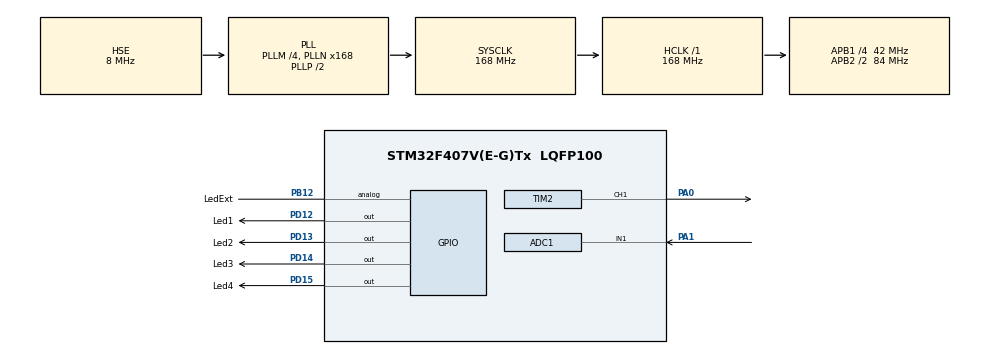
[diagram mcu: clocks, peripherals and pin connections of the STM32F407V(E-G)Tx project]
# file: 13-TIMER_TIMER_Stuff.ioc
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ADC1.Channel-3\#ChannelRegularConversion=ADC_CHANNEL_1
ADC1.ContinuousConvMode=DISABLE
ADC1.EOCSelection=ADC_EOC_SINGLE_CONV
ADC1.ExternalTrigConv=ADC_EXTERNALTRIGCONV_T3_TRGO
ADC1.NbrOfConversion=1
ADC1.NbrOfConversionFlag=1
ADC1.Rank-3\#ChannelRegularConversion=1
ADC1.Resolution=ADC_RESOLUTION_12B
ADC1.SamplingTime-3\#ChannelRegularConversion=ADC_SAMPLETIME_28CYCLES
ADC1.ScanConvMode=DISABLE
ADC1.master=1
Mcu.Family=STM32F4
Mcu.Name=STM32F407V(E-G)Tx
Mcu.Package=LQFP100
NVIC.ADC_IRQn=true\:0\:0\:false\:false\:true\:true\:true
NVIC.PriorityGroup=NVIC_PRIORITYGROUP_4
PA0-WKUP.Signal=S_TIM2_CH1_ETR
PA1.Signal=ADCx_IN1
PB12.GPIO_Label=LedExt
PB12.Signal=GPIO_Analog
PD12.GPIO_Label=Led1
PD12.Signal=GPIO_Output
PD13.GPIO_Label=Led2
PD13.Signal=GPIO_Output
PD14.GPIO_Label=Led3
PD14.Signal=GPIO_Output
PD15.GPIO_Label=Led4
PD15.Signal=GPIO_Output
PH0-OSC_IN.Mode=HSE-External-Oscillator
PH0-OSC_IN.Signal=RCC_OSC_IN
PH1-OSC_OUT.Mode=HSE-External-Oscillator
PH1-OSC_OUT.Signal=RCC_OSC_OUT
ProjectManager.HeapSize=0x200
ProjectManager.StackSize=0x400
ProjectManager.TargetToolchain=MDK-ARM V5.27
RCC.48MHZClocksFreq_Value=84000000
RCC.AHBFreq_Value=168000000
RCC.APB1CLKDivider=RCC_HCLK_DIV4
RCC.APB1Freq_Value=42000000
RCC.APB1TimFreq_Value=84000000
RCC.APB2CLKDivider=RCC_HCLK_DIV2
RCC.APB2Freq_Value=84000000
RCC.APB2TimFreq_Value=168000000
RCC.CortexFreq_Value=168000000
RCC.HCLKFreq_Value=168000000
RCC.HSE_VALUE=8000000
RCC.HSI_VALUE=16000000
RCC.LSE_VALUE=32768
RCC.PLLM=4
RCC.PLLN=168
RCC.PLLSourceVirtual=RCC_PLLSOURCE_HSE
RCC.SYSCLKFreq_VALUE=168000000
RCC.SYSCLKSource=RCC_SYSCLKSOURCE_PLLCLK
RCC.VCOOutputFreq_Value=336000000
SH.ADCx_IN1.0=ADC1_IN1,IN1
SH.S_TIM2_CH1_ETR.0=TIM2_CH1,PWM Generation1 CH1
TIM2.AutoReloadPreload=TIM_AUTORELOAD_PRELOAD_ENABLE
TIM2.Channel-PWM\ Generation1\ CH1=TIM_CHANNEL_1
TIM2.Period=65535
TIM3.AutoReloadPreload=TIM_AUTORELOAD_PRELOAD_ENABLE
TIM3.Period=8400
TIM3.Prescaler=1000
TIM3.TIM_MasterOutputTrigger=TIM_TRGO_UPDATE
VP_TIM2_VS_ClockSourceINT.Mode=Internal
VP_TIM3_VS_ClockSourceINT.Mode=Internal
board=custom

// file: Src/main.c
/* USER CODE BEGIN Header */
/**
  ******************************************************************************
  * @file           : main.c
  * @brief          : Main program body
  ******************************************************************************
  * @attention
  *
  * <h2><center>&copy; Copyright (c) 2020 STMicroelectronics.
  * All rights reserved.</center></h2>
  *
  * This software component is licensed by ST under BSD 3-Clause license,
  * the "License"; You may not use this file except in compliance with the
  * License. You may obtain a copy of the License at:
  *                        opensource.org/licenses/BSD-3-Clause
  *
  ******************************************************************************
  */
/* USER CODE END Header */

#include "main.h"

ADC_HandleTypeDef hadc1;

TIM_HandleTypeDef htim2;
TIM_HandleTypeDef htim3;

void SystemClock_Config(void);
static void MX_GPIO_Init(void);
static void MX_TIM2_Init(void);
static void MX_TIM3_Init(void);
static void MX_ADC1_Init(void);

/* USER CODE BEGIN 0 */
int32_t CH1_DC = 0;
uint16_t load;
uint16_t adcval;
/* USER CODE END 0 */

int main(void)
{

  /* MCU Configuration--------------------------------------------------------*/

  /* Reset of all peripherals, Initializes the Flash interface and the Systick. */
  HAL_Init();

  /* Configure the system clock */
  SystemClock_Config();

  /* Initialize all configured peripherals */
  MX_GPIO_Init();
  MX_TIM2_Init();
  MX_TIM3_Init();
  MX_ADC1_Init();
  /* USER CODE BEGIN 2 */

	HAL_ADC_Start_IT(&hadc1);
	HAL_TIM_Base_Start(&htim3);

	HAL_TIM_PWM_Start(&htim2, TIM_CHANNEL_1);

	//CH1_DC = 65534;
  /* USER CODE END 2 */

  /* Infinite loop */
  while (1)
  {

    /* USER CODE BEGIN 3 */

//		while(CH1_DC < 65535)
//    	{
//    	    TIM2->CCR1 = CH1_DC; // = CH1_DC
//    	    CH1_DC+=50;				 // += 70;
//    	    HAL_Delay(1);
//    	}
//    	while(CH1_DC > 0)
//    	{
//    	    TIM2->CCR1 = CH1_DC; //TIM2->CCR1 = CH1_DC;
//    	    CH1_DC-=50;
//    	    HAL_Delay(1);
//    	}
//			HAL_Delay(500);

	//		TIM2->CCR1 = adcval*16;
  }
  /* USER CODE END 3 */
}

void SystemClock_Config(void)
{
  RCC_OscInitTypeDef RCC_OscInitStruct = {0};
  RCC_ClkInitTypeDef RCC_ClkInitStruct = {0};

  /** Configure the main internal regulator output voltage
  */
  __HAL_RCC_PWR_CLK_ENABLE();
  __HAL_PWR_VOLTAGESCALING_CONFIG(PWR_REGULATOR_VOLTAGE_SCALE1);
  /** Initializes the CPU, AHB and APB busses clocks
  */
  RCC_OscInitStruct.OscillatorType = RCC_OSCILLATORTYPE_HSE;
  RCC_OscInitStruct.HSEState = RCC_HSE_ON;
  RCC_OscInitStruct.PLL.PLLState = RCC_PLL_ON;
  RCC_OscInitStruct.PLL.PLLSource = RCC_PLLSOURCE_HSE;
  RCC_OscInitStruct.PLL.PLLM = 4;
  RCC_OscInitStruct.PLL.PLLN = 168;
  RCC_OscInitStruct.PLL.PLLP = RCC_PLLP_DIV2;
  RCC_OscInitStruct.PLL.PLLQ = 4;
  if (HAL_RCC_OscConfig(&RCC_OscInitStruct) != HAL_OK)
  {
    Error_Handler();
  }
  /** Initializes the CPU, AHB and APB busses clocks
  */
  RCC_ClkInitStruct.ClockType = RCC_CLOCKTYPE_HCLK|RCC_CLOCKTYPE_SYSCLK
                              |RCC_CLOCKTYPE_PCLK1|RCC_CLOCKTYPE_PCLK2;
  RCC_ClkInitStruct.SYSCLKSource = RCC_SYSCLKSOURCE_PLLCLK;
  RCC_ClkInitStruct.AHBCLKDivider = RCC_SYSCLK_DIV1;
  RCC_ClkInitStruct.APB1CLKDivider = RCC_HCLK_DIV4;
  RCC_ClkInitStruct.APB2CLKDivider = RCC_HCLK_DIV2;

  if (HAL_RCC_ClockConfig(&RCC_ClkInitStruct, FLASH_LATENCY_5) != HAL_OK)
  {
    Error_Handler();
  }
}

static void MX_ADC1_Init(void)
{

  ADC_ChannelConfTypeDef sConfig = {0};

  /** Configure the global features of the ADC (Clock, Resolution, Data Alignment and number of conversion)
  */
  hadc1.Instance = ADC1;
  hadc1.Init.ClockPrescaler = ADC_CLOCK_SYNC_PCLK_DIV4;
  hadc1.Init.Resolution = ADC_RESOLUTION_12B;
  hadc1.Init.ScanConvMode = DISABLE;
  hadc1.Init.ContinuousConvMode = DISABLE;
  hadc1.Init.DiscontinuousConvMode = DISABLE;
  hadc1.Init.ExternalTrigConvEdge = ADC_EXTERNALTRIGCONVEDGE_RISING;
  hadc1.Init.ExternalTrigConv = ADC_EXTERNALTRIGCONV_T3_TRGO;
  hadc1.Init.DataAlign = ADC_DATAALIGN_RIGHT;
  hadc1.Init.NbrOfConversion = 1;
  hadc1.Init.DMAContinuousRequests = DISABLE;
  hadc1.Init.EOCSelection = ADC_EOC_SINGLE_CONV;
  if (HAL_ADC_Init(&hadc1) != HAL_OK)
  {
    Error_Handler();
  }
  /** Configure for the selected ADC regular channel its corresponding rank in the sequencer and its sample time.
  */
  sConfig.Channel = ADC_CHANNEL_1;
  sConfig.Rank = 1;
  sConfig.SamplingTime = ADC_SAMPLETIME_28CYCLES;
  if (HAL_ADC_ConfigChannel(&hadc1, &sConfig) != HAL_OK)
  {
    Error_Handler();
  }

}

static void MX_TIM2_Init(void)
{

  TIM_ClockConfigTypeDef sClockSourceConfig = {0};
  TIM_MasterConfigTypeDef sMasterConfig = {0};
  TIM_OC_InitTypeDef sConfigOC = {0};

  htim2.Instance = TIM2;
  htim2.Init.Prescaler = 0;
  htim2.Init.CounterMode = TIM_COUNTERMODE_UP;
  htim2.Init.Period = 65535;
  htim2.Init.ClockDivision = TIM_CLOCKDIVISION_DIV1;
  htim2.Init.AutoReloadPreload = TIM_AUTORELOAD_PRELOAD_ENABLE;
  if (HAL_TIM_Base_Init(&htim2) != HAL_OK)
  {
    Error_Handler();
  }
  sClockSourceConfig.ClockSource = TIM_CLOCKSOURCE_INTERNAL;
  if (HAL_TIM_ConfigClockSource(&htim2, &sClockSourceConfig) != HAL_OK)
  {
    Error_Handler();
  }
  if (HAL_TIM_PWM_Init(&htim2) != HAL_OK)
  {
    Error_Handler();
  }
  sMasterConfig.MasterOutputTrigger = TIM_TRGO_RESET;
  sMasterConfig.MasterSlaveMode = TIM_MASTERSLAVEMODE_DISABLE;
  if (HAL_TIMEx_MasterConfigSynchronization(&htim2, &sMasterConfig) != HAL_OK)
  {
    Error_Handler();
  }
  sConfigOC.OCMode = TIM_OCMODE_PWM1;
  sConfigOC.Pulse = 0;
  sConfigOC.OCPolarity = TIM_OCPOLARITY_HIGH;
  sConfigOC.OCFastMode = TIM_OCFAST_DISABLE;
  if (HAL_TIM_PWM_ConfigChannel(&htim2, &sConfigOC, TIM_CHANNEL_1) != HAL_OK)
  {
    Error_Handler();
  }
  HAL_TIM_MspPostInit(&htim2);

}

static void MX_TIM3_Init(void)
{

  TIM_ClockConfigTypeDef sClockSourceConfig = {0};
  TIM_MasterConfigTypeDef sMasterConfig = {0};

  htim3.Instance = TIM3;
  htim3.Init.Prescaler = 1000;
  htim3.Init.CounterMode = TIM_COUNTERMODE_UP;
  htim3.Init.Period = 8400;
  htim3.Init.ClockDivision = TIM_CLOCKDIVISION_DIV1;
  htim3.Init.AutoReloadPreload = TIM_AUTORELOAD_PRELOAD_ENABLE;
  if (HAL_TIM_Base_Init(&htim3) != HAL_OK)
  {
    Error_Handler();
  }
  sClockSourceConfig.ClockSource = TIM_CLOCKSOURCE_INTERNAL;
  if (HAL_TIM_ConfigClockSource(&htim3, &sClockSourceConfig) != HAL_OK)
  {
    Error_Handler();
  }
  sMasterConfig.MasterOutputTrigger = TIM_TRGO_UPDATE;
  sMasterConfig.MasterSlaveMode = TIM_MASTERSLAVEMODE_DISABLE;
  if (HAL_TIMEx_MasterConfigSynchronization(&htim3, &sMasterConfig) != HAL_OK)
  {
    Error_Handler();
  }

}

static void MX_GPIO_Init(void)
{
  GPIO_InitTypeDef GPIO_InitStruct = {0};

  /* GPIO Ports Clock Enable */
  __HAL_RCC_GPIOH_CLK_ENABLE();
  __HAL_RCC_GPIOA_CLK_ENABLE();
  __HAL_RCC_GPIOB_CLK_ENABLE();
  __HAL_RCC_GPIOD_CLK_ENABLE();

  /*Configure GPIO pin Output Level */
  HAL_GPIO_WritePin(GPIOD, Led1_Pin|Led2_Pin|Led3_Pin|Led4_Pin, GPIO_PIN_RESET);

  /*Configure GPIO pin : LedExt_Pin */
  GPIO_InitStruct.Pin = LedExt_Pin;
  GPIO_InitStruct.Mode = GPIO_MODE_ANALOG;
  GPIO_InitStruct.Pull = GPIO_NOPULL;
  HAL_GPIO_Init(LedExt_GPIO_Port, &GPIO_InitStruct);

  /*Configure GPIO pins : Led1_Pin Led2_Pin Led3_Pin Led4_Pin */
  GPIO_InitStruct.Pin = Led1_Pin|Led2_Pin|Led3_Pin|Led4_Pin;
  GPIO_InitStruct.Mode = GPIO_MODE_OUTPUT_PP;
  GPIO_InitStruct.Pull = GPIO_NOPULL;
  GPIO_InitStruct.Speed = GPIO_SPEED_FREQ_LOW;
  HAL_GPIO_Init(GPIOD, &GPIO_InitStruct);

}

/* USER CODE BEGIN 4 */

void HAL_ADC_ConvCpltCallback(ADC_HandleTypeDef* hadc)
{
  /* Prevent unused argument(s) compilation warning */
  UNUSED(hadc);
  /* NOTE : This function Should not be modified, when the callback is needed,
            the HAL_ADC_ConvCpltCallback could be implemented in the user file
   */
	adcval= HAL_ADC_GetValue(&hadc1);
	HAL_GPIO_TogglePin(GPIOD, Led2_Pin);
	TIM2->CCR1= adcval*16;
}

//void HAL_TIM_PeriodElapsedCallback(TIM_HandleTypeDef *htim)
//{
//  /* Prevent unused argument(s) compilation warning */
//  UNUSED(htim);

//  /* NOTE : This function should not be modified, when the callback is needed,
//            the HAL_TIM_PeriodElapsedCallback could be implemented in the user file
//   */
//	HAL_GPIO_TogglePin(GPIOD, Led1_Pin);
//
//	load= TIM2->CNT;

//}

/* USER CODE END 4 */

void Error_Handler(void)
{
}

/************************ (C) COPYRIGHT STMicroelectronics *****END OF FILE****/
